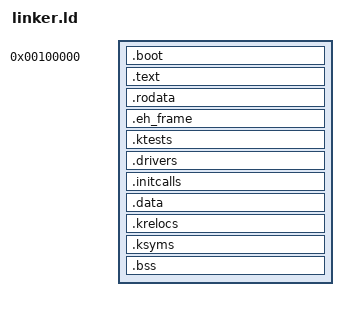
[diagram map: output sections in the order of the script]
ENTRY(_start)

/* Four PT_LOAD segments with real, distinct permission flags, rather
   than the one merged RWX segment this used to produce (which is what
   `ld: warning: kernel.bin has a LOAD segment with RWX permissions`
   was complaining about on every build). FLAGS() values are the
   standard ELF p_flags bits, PF_X=1 | PF_W=2 | PF_R=4.

   Nothing LOADS the kernel by these flags -- GRUB maps nothing, it
   copies the image in and jumps -- so unlike userland/rt/link.ld's
   equivalent split these are documentation plus a linker check, not
   enforcement. The enforcement is paging_enforce_wx()
   (kernel/arch/x86_64/paging.c), which reads the __ktext_start /
   __ktext_end / __kdata_start symbols below at boot and rewrites the
   identity map's permissions to match. The two must agree: a section
   that moves across one of those symbols changes its permissions. */
PHDRS
{
    boot   PT_LOAD FLAGS(4);
    text   PT_LOAD FLAGS(5);
    rodata PT_LOAD FLAGS(4);
    data   PT_LOAD FLAGS(6);
}

SECTIONS
{
    . = 1M;

    /* Every ALIGN(4096) below is load-bearing, not tidiness. W^X is
       enforced per 4KiB page, so two sections sharing a page must get
       the same permissions -- and the more permissive one always wins,
       which is the wrong direction every time. .text sharing a page
       with .rodata would make constants executable; sharing one with
       .data would make code writable. */
    __kimage_start = .;

    .boot :
    {
        *(.multiboot2)
    } :boot

    . = ALIGN(4096);
    __ktext_start = .;

    .text :
    {
        *(.text)
    } :text

    . = ALIGN(4096);
    __ktext_end = .;

    .rodata :
    {
        *(.rodata*)
    } :rodata

    /* Placed explicitly rather than left as an orphan: with PHDRS
       declared, where the linker puts an orphan section decides which
       segment (and therefore which permissions) it lands in, and
       "wherever ld felt like" is not a thing to leave to chance in a
       file whose whole job is now saying what is executable. */
    .eh_frame :
    {
        *(.eh_frame)
    } :rodata

    /* In-kernel test descriptors. KTEST() (kernel/include/kernel/ktest.h)
       drops one struct ktest_case per test into .ktests, and the runner
       walks the array between these two symbols -- so tests register
       themselves by existing, with no list to maintain by hand.
       ALIGN(8) matters: the entries are structs of pointers and the
       runner indexes them as an array, so any padding the linker
       inserted between input sections would be read as a bogus entry.
       They are `static const`, hence the read-only segment. */
    . = ALIGN(8);
    .ktests :
    {
        __ktests_start = .;
        KEEP(*(.ktests))
        __ktests_end = .;
    } :rodata

    /* Driver declarations. DRIVER_DECLARE() (kernel/include/api/driver.h)
       drops one struct driver_decl per driver into .drivers, and the
       registry walks the array between these two symbols -- so a driver
       is present in `lsdrv` by existing, not by reaching a call inside
       its own init(). Same mechanism and same ALIGN(8) reasoning as
       .ktests above; the entries are `static const`, hence :rodata.

       Above .krelocs for the reason that section's comment gives: every
       fixup location must sit in a section placed before the table that
       records it. */
    . = ALIGN(8);
    .drivers :
    {
        __drivers_start = .;
        KEEP(*(.drivers))
        __drivers_end = .;
    } :rodata

    /* Initcalls. INITCALL() (kernel/include/kernel/initcall.h) drops one
       struct initcall per init function into .initcalls and
       initcalls_run() walks them a level at a time -- so an init runs by
       being declared, not by a line in kernel_main(). Same mechanism,
       alignment and placement reasoning as .drivers above. */
    . = ALIGN(8);
    .initcalls :
    {
        __initcalls_start = .;
        KEEP(*(.initcalls))
        __initcalls_end = .;
    } :rodata

    . = ALIGN(4096);
    __kdata_start = .;

    .data :
    {
        *(.data)
    } :data

    /* The kernel's own relocation table: one 32-bit entry per absolute
       reference in the image, generated by tools/genrelocs.py from a
       first link pass and linked into the second. See that tool and
       kernel/arch/x86_64/reloc.c.

       Its POSITION is the whole trick. Every fixup location lives in
       .text/.rodata/.eh_frame/.ktests/.drivers/.data, all of which
       are placed above this point -- so adding the table (or changing
       its size) cannot move a single address the table records, and
       the entries computed from the pass-1 image stay valid in the
       pass-2 image that contains them. Moving this section above .data instead
       makes 8 entries describe the image it displaced, which
       genrelocs.py's --verify catches and reports as exactly that.

       It must also stay BEFORE .bss: .bss is NOBITS, so an allocated
       section after it would force the file to materialise the 13MB
       gfx back buffer as real bytes on disk. */
    . = ALIGN(4);
    .krelocs :
    {
        __krelocs_start = .;
        KEEP(*(.krelocs))
        __krelocs_end = .;
    } :data

    /* The function symbol table a panic prints names from, generated by
       tools/gen_syms.py from a first link pass. Its POSITION is the same
       trick .krelocs uses above and for the same reason: every address
       the table records lives in .text, which is placed well above this
       point, so adding the table cannot move a single entry in it.
       gen_syms.py's --verify re-derives it from the final image and
       fails the build if that ever stops holding.

       Before .bss for the same reason .krelocs is: .bss is NOBITS, and
       an allocated section after it would force the 13MB back buffer to
       materialise as real bytes in the file. */
    . = ALIGN(4);
    .ksyms :
    {
        __ksyms_start = .;
        KEEP(*(.ksyms))
        __ksyms_end = .;
    } :data

    .bss :
    {
        *(COMMON)
        *(.bss)
    } :data

    . = ALIGN(4096);
    _kernel_end = .; /* first byte after everything the linker placed --
                         used by pmm.c to know what physical range to
                         reserve for the kernel image itself */
}
